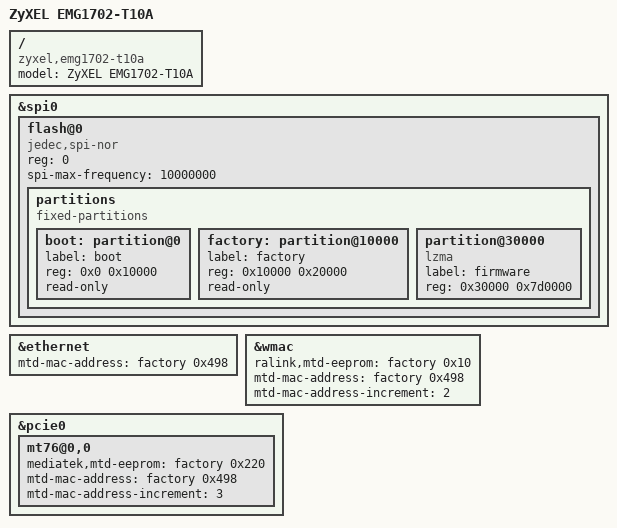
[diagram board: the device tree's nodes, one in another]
// SPDX-License-Identifier: GPL-2.0-or-later OR MIT

#include "mt7620a_tbs.dtsi"

/ {
	compatible = "zyxel,emg1702-t10a", "ralink,mt7620a-soc";
	model = "ZyXEL EMG1702-T10A";
};

&spi0 {
	status = "okay";

	flash@0 {
		compatible = "jedec,spi-nor";
		reg = <0>;
		spi-max-frequency = <10000000>;

		partitions {
			compatible = "fixed-partitions";
			#address-cells = <1>;
			#size-cells = <1>;

			boot: partition@0 {
				label = "boot";
				reg = <0x0 0x10000>;
				read-only;
			};

			factory: partition@10000 {
				label = "factory";
				reg = <0x10000 0x20000>;
				read-only;
			};

			partition@30000 {
				compatible = "lzma";
				label = "firmware";
				reg = <0x30000 0x7d0000>;
			};
		};
	};
};

&ethernet {
	mtd-mac-address = <&factory 0x498>;
};

&wmac {
	ralink,mtd-eeprom = <&factory 0x10>;
	mtd-mac-address = <&factory 0x498>;
	mtd-mac-address-increment = <2>;
};

&pcie0 {
	mt76@0,0 {
		mediatek,mtd-eeprom = <&factory 0x220>;
		mtd-mac-address = <&factory 0x498>;
		mtd-mac-address-increment = <3>;
	};
};
